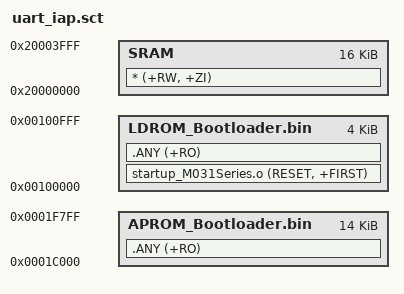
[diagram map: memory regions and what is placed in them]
LOAD_ROM_1  0x100000 0x1000
{
	LDROM_Bootloader.bin  0x100000 0x1000
	{
		startup_M031Series.o (RESET, +FIRST)
        .ANY (+RO)
	}
	
	SRAM  0x20000000 0x4000
	{
		* (+RW, +ZI)
	}
}

LOAD_ROM_2  0x1C000 0x3800
{
	APROM_Bootloader.bin  0x1C000 0x3800
	{
        .ANY (+RO)
	}
}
